# MEC1322 register map
Vendor: Microchip Technology Inc.; Series: ARMCM4F; File version: 1.0
CPU: CM4 r1p0, little endian, MPU, FPU, 3 interrupt priority bits
Registers are 32-bit, read-write, reset 0x0 unless marked. A register's access mark holds for its fields unless they carry their own. Offsets are from the block's base; [hi:lo] are bit positions; {n}, {i} and the like mark numbered series; 'fields as' and 'values as' point back to an identical list.

## HTM — The Hibernation Timer can generate a wake event to the Embedded Controller (EC) when it is in a hibernation mode. This block supports wake events up to 2 hours in duration. The timer is a 16-bit binary count-down timer that can be programmed in 30.5us and 0.125 second increments for period ranges of 30.5us to 2s or 0.125s to 136.5 minutes, respectively.
Base 0x40009800
0x00 PRELOAD 16-bit — [15:0] This register is used to set the Hibernation Timer Preload value.
0x04 CONTROL 16-bit — [0:0] 1= The Hibernation Timer has a resolution of 0.125s per LSB, which yields a maximum time in excess of 2 hours. 0= The Hibernation Timer has a resolution of 30.5us per LSB, which yields a maximum time of ~2seconds.
0x08 COUNT 16-bit read — The current state of the Hibernation Timer.

## RTC — This is the set of registers that are automatically counted by hardware every 1 second while the block is enabled to run and to update. These registers are: Seconds, Minutes, Hours, Day of Week, Day of Month, Month, and Year.
Base 0x400F2C00
0x00 SEC 8-bit — Seconds Register
0x01 SEC_ALARM 8-bit — Seconds Alarm Register
0x02 MIN 8-bit — Minutes Register
0x03 MIN_ALARM 8-bit — Minutes Alarm Register
0x04 HR 8-bit — Hours Register
0x05 HR_ALARM 8-bit — Hours Alarm Register
0x06 DAY_WEEK 8-bit — Day of Week Register
0x07 DAY_MONTH 8-bit — Day of Month Register
0x08 MONTH 8-bit
0x09 YEAR 8-bit
0x0A REG_A 8-bit — Register A
0x0B REG_B 8-bit — Register B
0x0C REG_C 8-bit — Register C
0x0D REG_D 8-bit — Register D
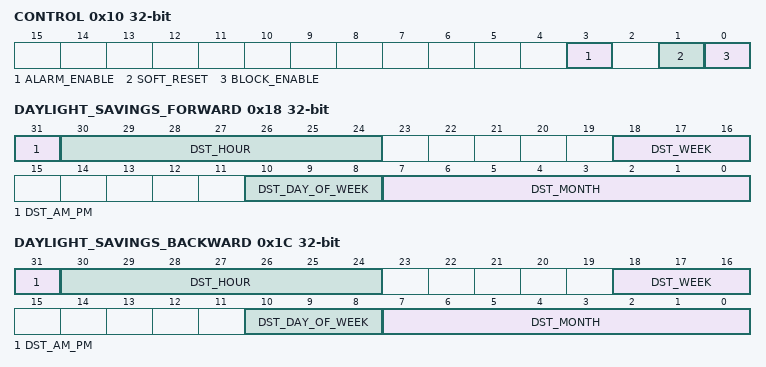
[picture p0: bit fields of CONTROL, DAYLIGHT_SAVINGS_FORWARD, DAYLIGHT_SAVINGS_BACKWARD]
0x10 CONTROL — RTC Control Register
  [3] ALARM_ENABLE — ALARM_ENABLE 1=Enables the Alarm features, 0=Disables the Alarm features
  [1] SOFT_RESET — SOFT_RESET A '1' written to this bit position will trigger the RTC_RST reset, resetting the block and all registers except this one and the Test Register. This bit is self-clearing at the end of the reset, one cycle of LPC Bus Clock later, and so requires no waiting.
  [0] BLOCK_ENABLE — BLOCK_ENABLE This bit must be '1' in order for the block to function internally. Registers may be initialized first, before setting this bit to '1' to start operation.
0x14 WEEK_ALARM (reset mask 0xFFFF) — Week Alarm Register[7:0] - ALARM_DAY_OF_WEEK This register, if written to a value in the range 1--7, will inhibit the Alarm interrupt unless this field matches the contents of the Day of Week Register also.
0x18 DAYLIGHT_SAVINGS_FORWARD
  [31] DST_AM_PM — This bit selects AM vs. PM, to match bit[7] of the Hours Register if 12-Hour mode is selected in Register B at the time of writing.
  [30:24] DST_HOUR — This field holds the matching value for bits[6:0] of the Hours register. The written value will be interpreted according to the 24/12 Hour mode and DM mode settings at the time of writing.
  [18:16] DST_WEEK — 5=Last week of month, 4 =Fourth week of month, 3=Third week of month, 2=Second week of month, 1=First week of month
  [10:8] DST_DAY_OF_WEEK — This field matches the Day of Week Register bits[2:0].
  [7:0] DST_MONTH — This field matches the Month Register.
0x1C DAYLIGHT_SAVINGS_BACKWARD
  fields as DAYLIGHT_SAVINGS_FORWARD

## GPIO — The MEC1322/24 GPIO Interface provides general purpose input monitoring and output control, as well as managing many aspects of pin functionality; including, multi-function. Pin Multiplexing Control, GPIO Direction control, PU/PD (PU_PD) resistors, asynchronous wakeup and synchronous Interrupt Detection (int_det), GPIO Direction, and Polarity control, as well as control of pin drive strength and slew rate.
Base 0x40081000
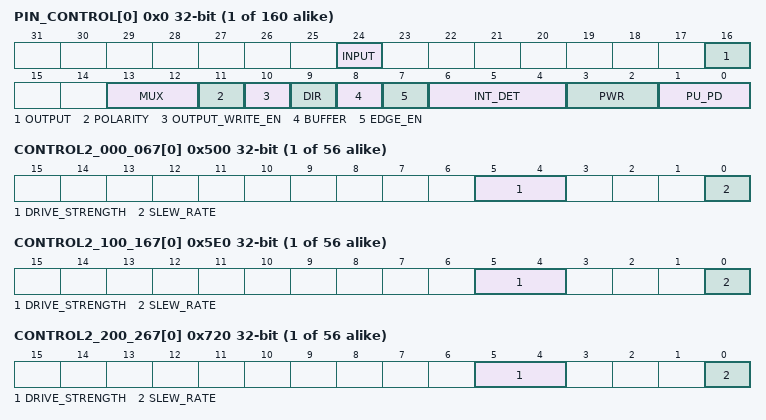
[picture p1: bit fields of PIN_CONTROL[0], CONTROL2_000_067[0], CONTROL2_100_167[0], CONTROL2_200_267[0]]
{0x0+4i} PIN_CONTROL[{i}] (i=0..159) — Two Pin Control Registers are implemented for each GPIO. That's the first one.
  [24] INPUT ro — On reads, Bit [24] reflects the state of GPIO input from the pad regardless of setting of Bit [10].
  [16] OUTPUT — On writes: If enabled via the Output GPIO Write Enable, 0: GPIO[x] out = '0', 1: GPIO[x] out = '1'
  [13:12] MUX — 00 = GPIO Function Selected, 01 = Signal Function 1 Selected, 10 = Signal Function 2 Selected, 11 = Signal Function 3 Selected
  [11] POLARITY — 0 = Non-inverted, 1 = Inverted
  [10] OUTPUT_WRITE_EN — 0 = Alternative GPIO data write enabled When this bit is zero the Alternative GPIO data write is enabled and the Output GPIO is disabled. 1 = Output GPIO enable When this bit is one the Alternative GPIO data write is disabled and the Output GPIO is enabled.
  [9] DIR — GPIO Direction. 0 = Input, 1 = Output
  [8] BUFFER — Output Buffer Type. 0 = Push-Pull, 1 = Open Drain
  [7] EDGE_EN — Edge Enable, 0 = Edge detection disabled, 1 = Edge detection enabled
  [6:4] INT_DET — 0 000 = Low Level Sensitive, 0 001 = High Level Sensitive. 0 100 = Interrupt events are disabled. 1 101 = Rising Edge Triggered. 1 110 = Falling Edge Triggered. 1 111 = Either edge triggered
  [3:2] PWR — Power Gating Signals. 00 = VCC1 Power Rail 01 = VCC2 Power Rail 1x = Reserved
  [1:0] PU_PD — PU/PD (PU_PD) 00 = None, 01 = Pull Up Enabled, 10 = Pull Down Enabled, 11 = None
{0x280+4i} OUTPUT[{i}] (i=0..4) — If enabled by the Output GPIO Write Enable bit, the GPIO Output bits determine the level on the GPIO pin when the pin is configured for the GPIO output function. On writes: If enabled via the Output GPIO Write Enable 0: GPIO[x] out = '0', 1: GPIO[x] out = '1'
{0x300+4i} INPUT[{i}] (i=0..4) — The GPIO Input Registers can always be used to read the state of a pin, even when the pin is in an output mode and/or when a signal function other than the GPIO signal function is selected
{0x500+4i} CONTROL2_000_067[{i}] (i=0..55) — PIN CONTROL REGISTER 2, from 000 - 067
  [5:4] DRIVE_STRENGTH — These bits are used to select the drive strength on the pin. [5:4] = 00 = 2mA, 01 = 4mA, 10 = 8mA, 11 = 12mA
  [0] SLEW_RATE — This bit is used to select the slew rate on the pin. 0 = slow (half frequency), 1 = fast
{0x5E0+4i} CONTROL2_100_167[{i}] (i=0..55) — PIN CONTROL REGISTER 2, from 100 - 167
  fields as CONTROL2_000_067[0]
{0x720+4i} CONTROL2_200_267[{i}] (i=0..55) — PIN CONTROL REGISTER 2, from 200 - 267
  fields as CONTROL2_000_067[0]
